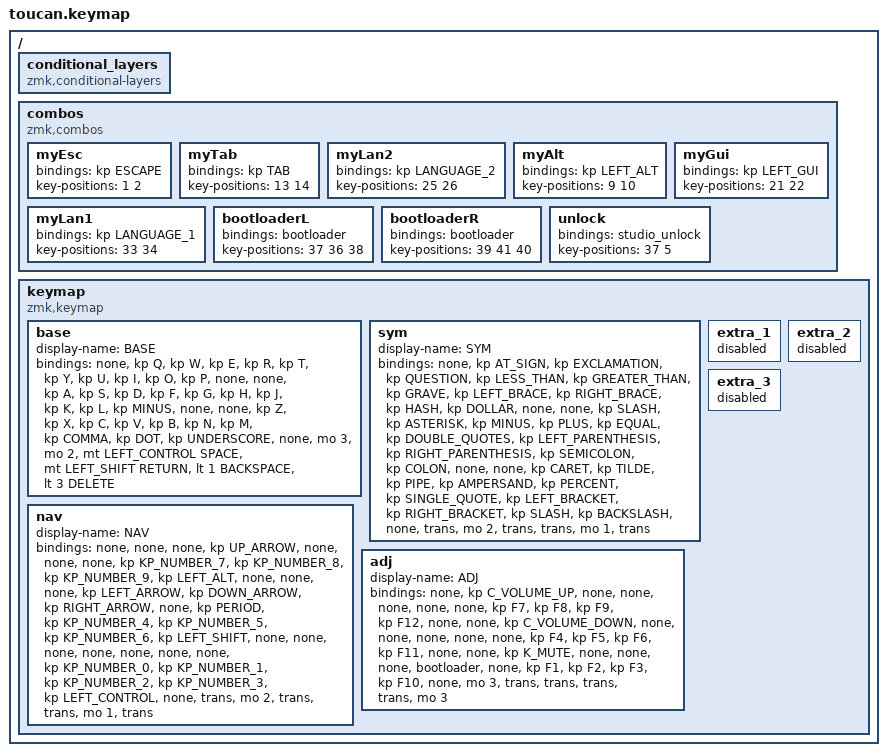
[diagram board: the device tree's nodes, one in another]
#include <behaviors.dtsi>
#include <dt-bindings/zmk/keys.h>

#define BASE 0
#define NAV  1
#define SYM  2
#define ADJ  3

/ {
    conditional_layers { compatible = "zmk,conditional-layers"; };

    combos {
        compatible = "zmk,combos";

        myEsc {
            bindings = <&kp ESCAPE>;
            key-positions = <1 2>;
        };

        myTab {
            bindings = <&kp TAB>;
            key-positions = <13 14>;
        };

        myLan2 {
            bindings = <&kp LANGUAGE_2>;
            key-positions = <25 26>;
        };

        myAlt {
            bindings = <&kp LEFT_ALT>;
            key-positions = <9 10>;
        };

        myGui {
            bindings = <&kp LEFT_GUI>;
            key-positions = <21 22>;
        };

        myLan1 {
            bindings = <&kp LANGUAGE_1>;
            key-positions = <33 34>;
        };

        bootloaderL {
            bindings = <&bootloader>;
            key-positions = <37 36 38>;
        };

        bootloaderR {
            bindings = <&bootloader>;
            key-positions = <39 41 40>;
        };

        unlock {
            bindings = <&studio_unlock>;
            key-positions = <37 5>;
        };
    };

    keymap {
        compatible = "zmk,keymap";

        base {
            display-name = "BASE";
            bindings = <
&none  &kp Q  &kp W  &kp E  &kp R  &kp T  &kp Y  &kp U  &kp I  &kp O  &kp P  &none  &none  &kp A  &kp S  &kp D  &kp F  &kp G  &kp H  &kp J  &kp K  &kp L  &kp MINUS  &none  &none  &kp Z  &kp X  &kp C  &kp V  &kp B  &kp N  &kp M  &kp COMMA  &kp DOT  &kp UNDERSCORE  &none  &mo 3  &mo 2  &mt LEFT_CONTROL SPACE  &mt LEFT_SHIFT RETURN  &lt 1 BACKSPACE  &lt 3 DELETE
            >;
        };

        sym {
            display-name = "SYM";
            bindings = <
&none  &kp AT_SIGN  &kp EXCLAMATION  &kp QUESTION  &kp LESS_THAN  &kp GREATER_THAN  &kp GRAVE  &kp LEFT_BRACE  &kp RIGHT_BRACE  &kp HASH  &kp DOLLAR  &none  &none  &kp SLASH  &kp ASTERISK  &kp MINUS  &kp PLUS  &kp EQUAL  &kp DOUBLE_QUOTES  &kp LEFT_PARENTHESIS  &kp RIGHT_PARENTHESIS  &kp SEMICOLON  &kp COLON  &none  &none  &kp CARET  &kp TILDE  &kp PIPE  &kp AMPERSAND  &kp PERCENT  &kp SINGLE_QUOTE  &kp LEFT_BRACKET  &kp RIGHT_BRACKET  &kp SLASH  &kp BACKSLASH  &none  &trans  &mo 2  &trans  &trans  &mo 1  &trans
            >;
        };

        nav {
            display-name = "NAV";
            bindings = <
&none  &none  &none  &kp UP_ARROW  &none  &none  &none  &kp KP_NUMBER_7  &kp KP_NUMBER_8  &kp KP_NUMBER_9  &kp LEFT_ALT  &none  &none  &none  &kp LEFT_ARROW  &kp DOWN_ARROW  &kp RIGHT_ARROW  &none  &kp PERIOD  &kp KP_NUMBER_4  &kp KP_NUMBER_5  &kp KP_NUMBER_6  &kp LEFT_SHIFT  &none  &none  &none  &none  &none  &none  &none  &kp KP_NUMBER_0  &kp KP_NUMBER_1  &kp KP_NUMBER_2  &kp KP_NUMBER_3  &kp LEFT_CONTROL  &none  &trans  &mo 2  &trans  &trans  &mo 1  &trans
            >;
        };

        adj {
            display-name = "ADJ";
            bindings = <
&none  &kp C_VOLUME_UP  &none  &none  &none  &none  &none  &kp F7  &kp F8  &kp F9  &kp F12  &none  &none  &kp C_VOLUME_DOWN  &none  &none  &none  &none  &none  &kp F4  &kp F5  &kp F6  &kp F11  &none  &none  &kp K_MUTE  &none  &none  &none  &bootloader  &none  &kp F1  &kp F2  &kp F3  &kp F10  &none  &mo 3  &trans  &trans  &trans  &trans  &mo 3
            >;
        };

        extra_1 { status = "reserved"; };

        extra_2 { status = "reserved"; };

        extra_3 { status = "reserved"; };
    };
};
